AUTOSAR XML (schema 00051)
package /SwComponentTypes
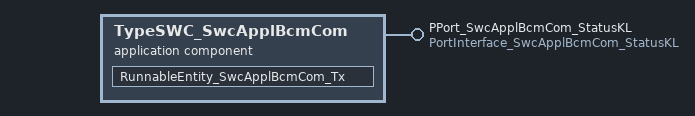
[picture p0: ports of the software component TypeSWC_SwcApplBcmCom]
  application sw component type TypeSWC_SwcApplBcmCom
    provide port PPort_SwcApplBcmCom_StatusKL: provided-interface=PortInterface_SwcApplBcmCom_StatusKL
    behavior InternalBehavior_SwcApplBcmCom_Tx: data-type-mapping=MappingSetTypeData_SwcApplBcmCom
      timing event TimingEvent_SwcApplBcmCom_Tx: start-on-event=RunnableEntity_SwcApplBcmCom_Tx
      runnable RunnableEntity_SwcApplBcmCom_Tx: symbol=FuncRunnableEntity_SwcApplBcmCom
        data-send-points:
          access DataSendPoint_DataElement_eKL30R: accessed-variable=PPort_SwcApplBcmCom_StatusKL.DataElement_eKL30R
